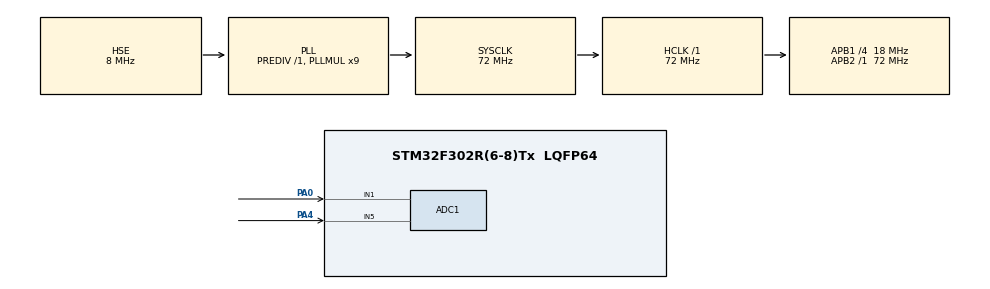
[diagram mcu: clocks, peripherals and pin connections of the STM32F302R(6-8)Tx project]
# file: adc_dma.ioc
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ADC1.Channel-0\#ChannelRegularConversion=ADC_CHANNEL_1
ADC1.Channel-4\#ChannelRegularConversion=ADC_CHANNEL_5
ADC1.ContinuousConvMode=ENABLE
ADC1.DMAContinuousRequests=ENABLE
ADC1.EOCSelection=ADC_EOC_SEQ_CONV
ADC1.EnableInjectedConversion=DISABLE
ADC1.NbrOfConversion=2
ADC1.NbrOfConversionFlag=1
ADC1.Offset-0\#ChannelRegularConversion=0
ADC1.Offset-4\#ChannelRegularConversion=0
ADC1.OffsetNumber-0\#ChannelRegularConversion=ADC_OFFSET_NONE
ADC1.OffsetNumber-4\#ChannelRegularConversion=ADC_OFFSET_NONE
ADC1.Rank-0\#ChannelRegularConversion=1
ADC1.Rank-4\#ChannelRegularConversion=2
ADC1.SamplingTime-0\#ChannelRegularConversion=ADC_SAMPLETIME_601CYCLES_5
ADC1.SamplingTime-4\#ChannelRegularConversion=ADC_SAMPLETIME_601CYCLES_5
ADC1.master=1
Dma.ADC1.0.Direction=DMA_PERIPH_TO_MEMORY
Dma.ADC1.0.Instance=DMA1_Channel1
Dma.ADC1.0.MemDataAlignment=DMA_MDATAALIGN_HALFWORD
Dma.ADC1.0.MemInc=DMA_MINC_ENABLE
Dma.ADC1.0.Mode=DMA_CIRCULAR
Dma.ADC1.0.PeriphDataAlignment=DMA_PDATAALIGN_HALFWORD
Dma.ADC1.0.PeriphInc=DMA_PINC_DISABLE
Dma.ADC1.0.Priority=DMA_PRIORITY_LOW
Dma.Request0=ADC1
Mcu.Family=STM32F3
Mcu.Name=STM32F302R(6-8)Tx
Mcu.Package=LQFP64
NVIC.ADC1_IRQn=true\:0\:0\:false\:false\:true\:true\:true\:true
NVIC.DMA1_Channel1_IRQn=true\:0\:0\:false\:false\:true\:false\:true\:true
NVIC.PriorityGroup=NVIC_PRIORITYGROUP_0
PA0.GPIO_Mode=GPIO_MODE_ANALOG
PA0.GPIO_PuPd=GPIO_NOPULL
PA0.Mode=IN1-Single-Ended
PA0.Signal=ADC1_IN1
PA13.Mode=Serial_Wire
PA13.Signal=SYS_JTMS-SWDIO
PA14.Mode=Serial_Wire
PA14.Signal=SYS_JTCK-SWCLK
PA4.Mode=IN5-Single-Ended
PA4.Signal=ADC1_IN5
PB3.GPIO_Label=SWO
PB3.Mode=Trace_Asynchronous_SW
PB3.Signal=SYS_JTDO-TRACESWO
PC14\ -\ OSC32_IN.Mode=LSE-External-Clock-Source
PC14\ -\ OSC32_IN.Signal=RCC_OSC32_IN
PF0-OSC_IN.Mode=HSE-External-Oscillator
PF0-OSC_IN.Signal=RCC_OSC_IN
PF1-OSC_OUT.Mode=HSE-External-Oscillator
PF1-OSC_OUT.Signal=RCC_OSC_OUT
ProjectManager.HeapSize=0x200
ProjectManager.StackSize=0x400
ProjectManager.TargetToolchain=STM32CubeIDE
RCC.ADC12PRES=RCC_ADC1PLLCLK_DIV6
RCC.AHBFreq_Value=72000000
RCC.APB1CLKDivider=RCC_HCLK_DIV4
RCC.APB1Freq_Value=18000000
RCC.APB1TimFreq_Value=36000000
RCC.APB2Freq_Value=72000000
RCC.APB2TimFreq_Value=72000000
RCC.CortexFreq_Value=72000000
RCC.HCLKFreq_Value=72000000
RCC.HSE_VALUE=8000000
RCC.HSI_VALUE=8000000
RCC.LSE_VALUE=32768
RCC.PLLM=8
RCC.PLLMUL=RCC_PLL_MUL9
RCC.PLLN=336
RCC.PLLP=RCC_PLLP_DIV4
RCC.PLLQ=7
RCC.PLLSourceVirtual=RCC_PLLSOURCE_HSE
RCC.SYSCLKFreq_VALUE=72000000
RCC.SYSCLKSourceVirtual=RCC_SYSCLKSOURCE_PLLCLK
RCC.USBFreq_Value=72000000
board=NUCLEO-F302R8

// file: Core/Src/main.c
/* USER CODE BEGIN Header */
/**
  ******************************************************************************
  * @file           : main.c
  * @brief          : Main program body
  ******************************************************************************
  * @attention
  *
  * Copyright (c) 2026 STMicroelectronics.
  * All rights reserved.
  *
  * This software is licensed under terms that can be found in the LICENSE file
  * in the root directory of this software component.
  * If no LICENSE file comes with this software, it is provided AS-IS.
  *
  ******************************************************************************
  */
/* USER CODE END Header */
#include "main.h"
#include "adc.h"
#include "dma.h"
#include "gpio.h"

/* USER CODE BEGIN PV */
uint16_t data[2];
float vref = 3.3;
float max_val=4095.0;
float data1,data2;

/* USER CODE END PV */

void SystemClock_Config(void);

int main(void)
{

  /* MCU Configuration--------------------------------------------------------*/

  /* Reset of all peripherals, Initializes the Flash interface and the Systick. */
  HAL_Init();

  /* Configure the system clock */
  SystemClock_Config();

  /* Initialize all configured peripherals */
  MX_GPIO_Init();
  MX_DMA_Init();
  MX_ADC1_Init();
  /* USER CODE BEGIN 2 */
  HAL_ADC_Start_DMA(&hadc1, (uint32_t*)data, 2);

  /* USER CODE END 2 */

  /* Infinite loop */
  while (1)
  {

  }
}

void SystemClock_Config(void)
{
  RCC_OscInitTypeDef RCC_OscInitStruct = {0};
  RCC_ClkInitTypeDef RCC_ClkInitStruct = {0};
  RCC_PeriphCLKInitTypeDef PeriphClkInit = {0};

  /** Initializes the RCC Oscillators according to the specified parameters
  * in the RCC_OscInitTypeDef structure.
  */
  RCC_OscInitStruct.OscillatorType = RCC_OSCILLATORTYPE_HSE;
  RCC_OscInitStruct.HSEState = RCC_HSE_ON;
  RCC_OscInitStruct.HSEPredivValue = RCC_HSE_PREDIV_DIV1;
  RCC_OscInitStruct.HSIState = RCC_HSI_ON;
  RCC_OscInitStruct.PLL.PLLState = RCC_PLL_ON;
  RCC_OscInitStruct.PLL.PLLSource = RCC_PLLSOURCE_HSE;
  RCC_OscInitStruct.PLL.PLLMUL = RCC_PLL_MUL9;
  if (HAL_RCC_OscConfig(&RCC_OscInitStruct) != HAL_OK)
  {
    Error_Handler();
  }

  /** Initializes the CPU, AHB and APB buses clocks
  */
  RCC_ClkInitStruct.ClockType = RCC_CLOCKTYPE_HCLK|RCC_CLOCKTYPE_SYSCLK
                              |RCC_CLOCKTYPE_PCLK1|RCC_CLOCKTYPE_PCLK2;
  RCC_ClkInitStruct.SYSCLKSource = RCC_SYSCLKSOURCE_PLLCLK;
  RCC_ClkInitStruct.AHBCLKDivider = RCC_SYSCLK_DIV1;
  RCC_ClkInitStruct.APB1CLKDivider = RCC_HCLK_DIV4;
  RCC_ClkInitStruct.APB2CLKDivider = RCC_HCLK_DIV1;

  if (HAL_RCC_ClockConfig(&RCC_ClkInitStruct, FLASH_LATENCY_2) != HAL_OK)
  {
    Error_Handler();
  }
  PeriphClkInit.PeriphClockSelection = RCC_PERIPHCLK_ADC1;
  PeriphClkInit.Adc1ClockSelection = RCC_ADC1PLLCLK_DIV6;

  if (HAL_RCCEx_PeriphCLKConfig(&PeriphClkInit) != HAL_OK)
  {
    Error_Handler();
  }
}

/* USER CODE BEGIN 4 */
void HAL_ADC_ConvCpltCallback(ADC_HandleTypeDef* hadc)
{
	 data1 = (data[0] * vref) / max_val;
	 data2 = (data[1] * vref) / max_val; ;
}

/* USER CODE END 4 */

void Error_Handler(void)
{
  __disable_irq();
  while (1)
  {
  }
}
